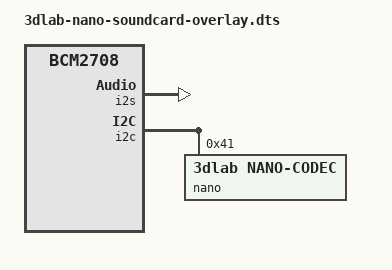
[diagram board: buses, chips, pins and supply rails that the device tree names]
// Definitions for 3Dlab Nano soundcard
/dts-v1/;
/plugin/;

/ {
	compatible = "brcm,bcm2708";

	fragment@0 {
		target = <&i2s>;
		__overlay__ {
			status = "okay";
		};
	};

	fragment@1 {
		target = <&i2c>;
		__overlay__ {
			#address-cells = <1>;
			#size-cells = <0>;
			status = "okay";

			nano: nano-codec@41 {
				#sound-dai-cells = <0>;
				compatible = "3dlab,nano-codec";
				reg = <0x41>;
				status = "okay";
			};
		};
	};

	fragment@2 {
		target = <&sound>;
		__overlay__ {
			compatible = "3dlab,nano-soundcard";
			i2s-controller = <&i2s>;
			i2s-interface = <&nano>;
			status = "okay";
		};
	};
};

// EOF
